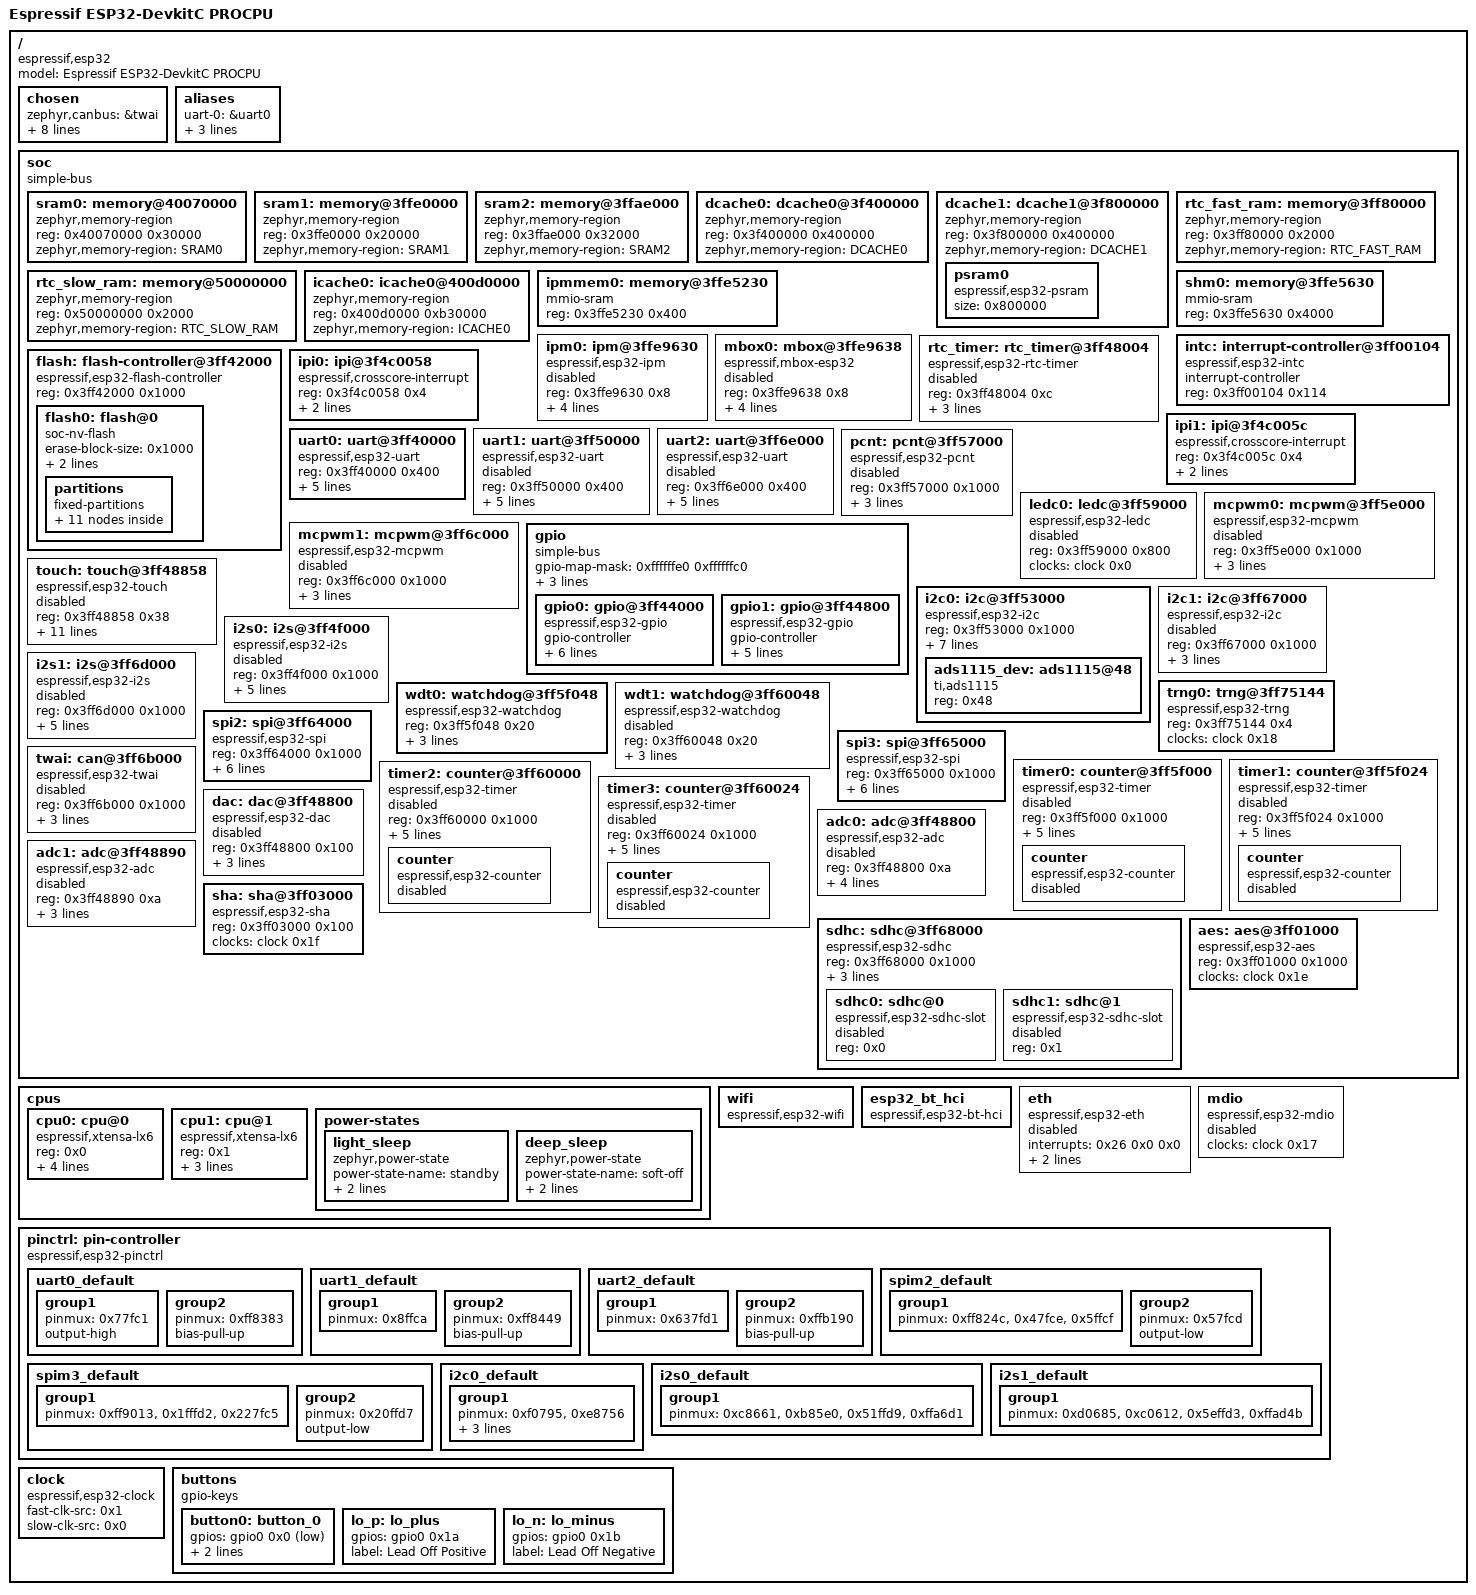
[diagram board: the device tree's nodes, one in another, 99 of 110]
/dts-v1/;

/* node '/' defined in zephyr/dts/common/skeleton.dtsi:9 */
/ {
	#address-cells = < 0x1 >;                 /* in zephyr/dts/common/skeleton.dtsi:10 */
	#size-cells = < 0x1 >;                    /* in zephyr/dts/common/skeleton.dtsi:11 */
	model = "Espressif ESP32-DevkitC PROCPU"; /* in zephyr/boards/espressif/esp32_devkitc/esp32_devkitc_procpu.dts:15 */
	compatible = "espressif,esp32";           /* in zephyr/boards/espressif/esp32_devkitc/esp32_devkitc_procpu.dts:16 */

	/* node '/chosen' defined in zephyr/dts/common/skeleton.dtsi:13 */
	chosen {
		zephyr,canbus = &twai;                    /* in zephyr/dts/xtensa/espressif/esp32/esp32_common.dtsi:20 */
		zephyr,entropy = &trng0;                  /* in zephyr/dts/xtensa/espressif/esp32/esp32_common.dtsi:21 */
		zephyr,flash-controller = &flash;         /* in zephyr/dts/xtensa/espressif/esp32/esp32_common.dtsi:22 */
		zephyr,sram = &sram1;                     /* in zephyr/boards/espressif/esp32_devkitc/esp32_devkitc_procpu.dts:36 */
		zephyr,console = &uart0;                  /* in zephyr/boards/espressif/esp32_devkitc/esp32_devkitc_procpu.dts:37 */
		zephyr,shell-uart = &uart0;               /* in zephyr/boards/espressif/esp32_devkitc/esp32_devkitc_procpu.dts:38 */
		zephyr,flash = &flash0;                   /* in zephyr/boards/espressif/esp32_devkitc/esp32_devkitc_procpu.dts:39 */
		zephyr,code-partition = &slot0_partition; /* in zephyr/boards/espressif/esp32_devkitc/esp32_devkitc_procpu.dts:40 */
		zephyr,bt-hci = &esp32_bt_hci;            /* in zephyr/boards/espressif/esp32_devkitc/esp32_devkitc_procpu.dts:41 */
	};

	/* node '/aliases' defined in zephyr/dts/common/skeleton.dtsi:15 */
	aliases {
		uart-0 = &uart0;   /* in zephyr/boards/espressif/esp32_devkitc/esp32_devkitc_procpu.dts:19 */
		i2c-0 = &i2c0;     /* in zephyr/boards/espressif/esp32_devkitc/esp32_devkitc_procpu.dts:20 */
		sw0 = &button0;    /* in zephyr/boards/espressif/esp32_devkitc/esp32_devkitc_procpu.dts:21 */
		watchdog0 = &wdt0; /* in zephyr/boards/espressif/esp32_devkitc/esp32_devkitc_procpu.dts:22 */
	};

	/* node '/soc' defined in zephyr/dts/xtensa/xtensa.dtsi:10 */
	soc {
		#address-cells = < 0x1 >;  /* in zephyr/dts/xtensa/xtensa.dtsi:11 */
		#size-cells = < 0x1 >;     /* in zephyr/dts/xtensa/xtensa.dtsi:12 */
		compatible = "simple-bus"; /* in zephyr/dts/xtensa/xtensa.dtsi:13 */
		ranges;                    /* in zephyr/dts/xtensa/xtensa.dtsi:14 */

		/* node '/soc/memory@40070000' defined in zephyr/dts/xtensa/espressif/esp32/esp32_common.dtsi:106 */
		sram0: memory@40070000 {
			compatible = "zephyr,memory-region",
			             "mmio-sram";            /* in zephyr/dts/xtensa/espressif/esp32/esp32_common.dtsi:107 */
			reg = < 0x40070000 0x30000 >;        /* in zephyr/dts/xtensa/espressif/esp32/esp32_common.dtsi:108 */
			zephyr,memory-region = "SRAM0";      /* in zephyr/dts/xtensa/espressif/esp32/esp32_common.dtsi:109 */
		};

		/* node '/soc/memory@3ffe0000' defined in zephyr/dts/xtensa/espressif/esp32/esp32_common.dtsi:112 */
		sram1: memory@3ffe0000 {
			compatible = "zephyr,memory-region",
			             "mmio-sram";            /* in zephyr/dts/xtensa/espressif/esp32/esp32_common.dtsi:113 */
			reg = < 0x3ffe0000 0x20000 >;        /* in zephyr/dts/xtensa/espressif/esp32/esp32_common.dtsi:114 */
			zephyr,memory-region = "SRAM1";      /* in zephyr/dts/xtensa/espressif/esp32/esp32_common.dtsi:115 */
		};

		/* node '/soc/memory@3ffae000' defined in zephyr/dts/xtensa/espressif/esp32/esp32_common.dtsi:118 */
		sram2: memory@3ffae000 {
			compatible = "zephyr,memory-region",
			             "mmio-sram";            /* in zephyr/dts/xtensa/espressif/esp32/esp32_common.dtsi:119 */
			reg = < 0x3ffae000 0x32000 >;        /* in zephyr/dts/xtensa/espressif/esp32/esp32_common.dtsi:120 */
			zephyr,memory-region = "SRAM2";      /* in zephyr/dts/xtensa/espressif/esp32/esp32_common.dtsi:121 */
		};

		/* node '/soc/dcache0@3f400000' defined in zephyr/dts/xtensa/espressif/esp32/esp32_common.dtsi:124 */
		dcache0: dcache0@3f400000 {
			compatible = "zephyr,memory-region",
			             "mmio-sram";            /* in zephyr/dts/xtensa/espressif/esp32/esp32_common.dtsi:125 */
			reg = < 0x3f400000 0x400000 >;       /* in zephyr/dts/xtensa/espressif/esp32/esp32_common.dtsi:126 */
			zephyr,memory-region = "DCACHE0";    /* in zephyr/dts/xtensa/espressif/esp32/esp32_common.dtsi:127 */
		};

		/* node '/soc/dcache1@3f800000' defined in zephyr/dts/xtensa/espressif/esp32/esp32_common.dtsi:130 */
		dcache1: dcache1@3f800000 {
			compatible = "zephyr,memory-region",
			             "mmio-sram";            /* in zephyr/dts/xtensa/espressif/esp32/esp32_common.dtsi:131 */
			reg = < 0x3f800000 0x400000 >;       /* in zephyr/dts/xtensa/espressif/esp32/esp32_common.dtsi:132 */
			zephyr,memory-region = "DCACHE1";    /* in zephyr/dts/xtensa/espressif/esp32/esp32_common.dtsi:133 */

			/* node '/soc/dcache1@3f800000/psram0' defined in zephyr/dts/xtensa/espressif/esp32/esp32_common.dtsi:135 */
			psram0: psram0 {
				compatible = "espressif,esp32-psram"; /* in zephyr/dts/xtensa/espressif/esp32/esp32_common.dtsi:136 */
				size = < 0x800000 >;                  /* in zephyr/dts/xtensa/espressif/esp32/esp32_wrover_e_n4r8.dtsi:26 */
			};
		};

		/* node '/soc/memory@3ff80000' defined in zephyr/dts/xtensa/espressif/esp32/esp32_common.dtsi:141 */
		rtc_fast_ram: memory@3ff80000 {
			compatible = "zephyr,memory-region",
			             "mmio-sram";              /* in zephyr/dts/xtensa/espressif/esp32/esp32_common.dtsi:142 */
			reg = < 0x3ff80000 0x2000 >;           /* in zephyr/dts/xtensa/espressif/esp32/esp32_common.dtsi:143 */
			zephyr,memory-region = "RTC_FAST_RAM"; /* in zephyr/dts/xtensa/espressif/esp32/esp32_common.dtsi:144 */
		};

		/* node '/soc/memory@50000000' defined in zephyr/dts/xtensa/espressif/esp32/esp32_common.dtsi:147 */
		rtc_slow_ram: memory@50000000 {
			compatible = "zephyr,memory-region",
			             "mmio-sram";              /* in zephyr/dts/xtensa/espressif/esp32/esp32_common.dtsi:148 */
			reg = < 0x50000000 0x2000 >;           /* in zephyr/dts/xtensa/espressif/esp32/esp32_common.dtsi:149 */
			zephyr,memory-region = "RTC_SLOW_RAM"; /* in zephyr/dts/xtensa/espressif/esp32/esp32_common.dtsi:150 */
		};

		/* node '/soc/icache0@400d0000' defined in zephyr/dts/xtensa/espressif/esp32/esp32_common.dtsi:153 */
		icache0: icache0@400d0000 {
			compatible = "zephyr,memory-region",
			             "mmio-sram";            /* in zephyr/dts/xtensa/espressif/esp32/esp32_common.dtsi:154 */
			reg = < 0x400d0000 0xb30000 >;       /* in zephyr/dts/xtensa/espressif/esp32/esp32_common.dtsi:155 */
			zephyr,memory-region = "ICACHE0";    /* in zephyr/dts/xtensa/espressif/esp32/esp32_common.dtsi:156 */
		};

		/* node '/soc/memory@3ffe5230' defined in zephyr/dts/xtensa/espressif/esp32/esp32_common.dtsi:159 */
		ipmmem0: memory@3ffe5230 {
			compatible = "mmio-sram";   /* in zephyr/dts/xtensa/espressif/esp32/esp32_common.dtsi:160 */
			reg = < 0x3ffe5230 0x400 >; /* in zephyr/dts/xtensa/espressif/esp32/esp32_common.dtsi:161 */
			phandle = < 0x1 >;          /* in zephyr/dts/xtensa/espressif/esp32/esp32_common.dtsi:173 */
		};

		/* node '/soc/memory@3ffe5630' defined in zephyr/dts/xtensa/espressif/esp32/esp32_common.dtsi:164 */
		shm0: memory@3ffe5630 {
			compatible = "mmio-sram";    /* in zephyr/dts/xtensa/espressif/esp32/esp32_common.dtsi:165 */
			reg = < 0x3ffe5630 0x4000 >; /* in zephyr/dts/xtensa/espressif/esp32/esp32_common.dtsi:166 */
		};

		/* node '/soc/ipm@3ffe9630' defined in zephyr/dts/xtensa/espressif/esp32/esp32_common.dtsi:169 */
		ipm0: ipm@3ffe9630 {
			compatible = "espressif,esp32-ipm"; /* in zephyr/dts/xtensa/espressif/esp32/esp32_common.dtsi:170 */
			reg = < 0x3ffe9630 0x8 >;           /* in zephyr/dts/xtensa/espressif/esp32/esp32_common.dtsi:171 */
			status = "disabled";                /* in zephyr/dts/xtensa/espressif/esp32/esp32_common.dtsi:172 */
			shared-memory = < &ipmmem0 >;       /* in zephyr/dts/xtensa/espressif/esp32/esp32_common.dtsi:173 */
			shared-memory-size = < 0x400 >;     /* in zephyr/dts/xtensa/espressif/esp32/esp32_common.dtsi:174 */
			interrupts = < 0x18 0x0 0x0 >,
			             < 0x19 0x0 0x0 >;      /* in zephyr/dts/xtensa/espressif/esp32/esp32_common.dtsi:175 */
			interrupt-parent = < &intc >;       /* in zephyr/dts/xtensa/espressif/esp32/esp32_common.dtsi:177 */
		};

		/* node '/soc/mbox@3ffe9638' defined in zephyr/dts/xtensa/espressif/esp32/esp32_common.dtsi:180 */
		mbox0: mbox@3ffe9638 {
			compatible = "espressif,mbox-esp32"; /* in zephyr/dts/xtensa/espressif/esp32/esp32_common.dtsi:181 */
			reg = < 0x3ffe9638 0x8 >;            /* in zephyr/dts/xtensa/espressif/esp32/esp32_common.dtsi:182 */
			status = "disabled";                 /* in zephyr/dts/xtensa/espressif/esp32/esp32_common.dtsi:183 */
			shared-memory = < &ipmmem0 >;        /* in zephyr/dts/xtensa/espressif/esp32/esp32_common.dtsi:184 */
			shared-memory-size = < 0x400 >;      /* in zephyr/dts/xtensa/espressif/esp32/esp32_common.dtsi:185 */
			interrupts = < 0x18 0x0 0x0 >,
			             < 0x19 0x0 0x0 >;       /* in zephyr/dts/xtensa/espressif/esp32/esp32_common.dtsi:186 */
			interrupt-parent = < &intc >;        /* in zephyr/dts/xtensa/espressif/esp32/esp32_common.dtsi:188 */
			#mbox-cells = < 0x1 >;               /* in zephyr/dts/xtensa/espressif/esp32/esp32_common.dtsi:189 */
		};

		/* node '/soc/interrupt-controller@3ff00104' defined in zephyr/dts/xtensa/espressif/esp32/esp32_common.dtsi:192 */
		intc: interrupt-controller@3ff00104 {
			#interrupt-cells = < 0x3 >;          /* in zephyr/dts/xtensa/espressif/esp32/esp32_common.dtsi:193 */
			#address-cells = < 0x0 >;            /* in zephyr/dts/xtensa/espressif/esp32/esp32_common.dtsi:194 */
			compatible = "espressif,esp32-intc"; /* in zephyr/dts/xtensa/espressif/esp32/esp32_common.dtsi:195 */
			interrupt-controller;                /* in zephyr/dts/xtensa/espressif/esp32/esp32_common.dtsi:196 */
			reg = < 0x3ff00104 0x114 >;          /* in zephyr/dts/xtensa/espressif/esp32/esp32_common.dtsi:197 */
			status = "okay";                     /* in zephyr/dts/xtensa/espressif/esp32/esp32_common.dtsi:198 */
			phandle = < 0x2 >;                   /* in zephyr/dts/xtensa/espressif/esp32/esp32_common.dtsi:177 */
		};

		/* node '/soc/rtc_timer@3ff48004' defined in zephyr/dts/xtensa/espressif/esp32/esp32_common.dtsi:201 */
		rtc_timer: rtc_timer@3ff48004 {
			reg = < 0x3ff48004 0xc >;                 /* in zephyr/dts/xtensa/espressif/esp32/esp32_common.dtsi:202 */
			compatible = "espressif,esp32-rtc-timer"; /* in zephyr/dts/xtensa/espressif/esp32/esp32_common.dtsi:203 */
			clocks = < &clock 0x22 >;                 /* in zephyr/dts/xtensa/espressif/esp32/esp32_common.dtsi:204 */
			interrupts = < 0x2e 0x0 0x0 >;            /* in zephyr/dts/xtensa/espressif/esp32/esp32_common.dtsi:205 */
			interrupt-parent = < &intc >;             /* in zephyr/dts/xtensa/espressif/esp32/esp32_common.dtsi:206 */
			status = "disabled";                      /* in zephyr/dts/xtensa/espressif/esp32/esp32_common.dtsi:207 */
		};

		/* node '/soc/flash-controller@3ff42000' defined in zephyr/dts/xtensa/espressif/esp32/esp32_common.dtsi:210 */
		flash: flash-controller@3ff42000 {
			compatible = "espressif,esp32-flash-controller"; /* in zephyr/dts/xtensa/espressif/esp32/esp32_common.dtsi:211 */
			reg = < 0x3ff42000 0x1000 >;                     /* in zephyr/dts/xtensa/espressif/esp32/esp32_common.dtsi:212 */
			#address-cells = < 0x1 >;                        /* in zephyr/dts/xtensa/espressif/esp32/esp32_common.dtsi:213 */
			#size-cells = < 0x1 >;                           /* in zephyr/dts/xtensa/espressif/esp32/esp32_common.dtsi:214 */

			/* node '/soc/flash-controller@3ff42000/flash@0' defined in zephyr/dts/xtensa/espressif/esp32/esp32_common.dtsi:216 */
			flash0: flash@0 {
				compatible = "soc-nv-flash";   /* in zephyr/dts/xtensa/espressif/esp32/esp32_common.dtsi:217 */
				erase-block-size = < 0x1000 >; /* in zephyr/dts/xtensa/espressif/esp32/esp32_common.dtsi:218 */
				write-block-size = < 0x4 >;    /* in zephyr/dts/xtensa/espressif/esp32/esp32_common.dtsi:219 */
				reg = < 0x0 0x400000 >;        /* in zephyr/dts/xtensa/espressif/esp32/esp32_wrover_e_n4r8.dtsi:21 */

				/* node '/soc/flash-controller@3ff42000/flash@0/partitions' defined in zephyr/dts/vendor/espressif/partitions_0x1000_amp_4M.dtsi:8 */
				partitions {
					compatible = "fixed-partitions"; /* in zephyr/dts/vendor/espressif/partitions_0x1000_amp_4M.dtsi:9 */
					#address-cells = < 0x1 >;        /* in zephyr/dts/vendor/espressif/partitions_0x1000_amp_4M.dtsi:10 */
					#size-cells = < 0x1 >;           /* in zephyr/dts/vendor/espressif/partitions_0x1000_amp_4M.dtsi:11 */

					/* node '/soc/flash-controller@3ff42000/flash@0/partitions/partition@1000' defined in zephyr/dts/vendor/espressif/partitions_0x1000_amp_4M.dtsi:13 */
					boot_partition: partition@1000 {
						label = "mcuboot";       /* in zephyr/dts/vendor/espressif/partitions_0x1000_amp_4M.dtsi:14 */
						reg = < 0x1000 0xf000 >; /* in zephyr/dts/vendor/espressif/partitions_0x1000_amp_4M.dtsi:15 */
					};

					/* node '/soc/flash-controller@3ff42000/flash@0/partitions/partition@10000' defined in zephyr/dts/vendor/espressif/partitions_0x1000_amp_4M.dtsi:18 */
					sys_partition: partition@10000 {
						label = "sys";             /* in zephyr/dts/vendor/espressif/partitions_0x1000_amp_4M.dtsi:19 */
						reg = < 0x10000 0x10000 >; /* in zephyr/dts/vendor/espressif/partitions_0x1000_amp_4M.dtsi:20 */
					};

					/* node '/soc/flash-controller@3ff42000/flash@0/partitions/partition@20000' defined in zephyr/dts/vendor/espressif/partitions_0x1000_amp_4M.dtsi:23 */
					slot0_partition: partition@20000 {
						label = "image-0";          /* in zephyr/dts/vendor/espressif/partitions_0x1000_amp_4M.dtsi:24 */
						reg = < 0x20000 0x150000 >; /* in zephyr/dts/vendor/espressif/partitions_0x1000_amp_4M.dtsi:25 */
					};

					/* node '/soc/flash-controller@3ff42000/flash@0/partitions/partition@170000' defined in zephyr/dts/vendor/espressif/partitions_0x1000_amp_4M.dtsi:28 */
					slot1_partition: partition@170000 {
						label = "image-1";           /* in zephyr/dts/vendor/espressif/partitions_0x1000_amp_4M.dtsi:29 */
						reg = < 0x170000 0x150000 >; /* in zephyr/dts/vendor/espressif/partitions_0x1000_amp_4M.dtsi:30 */
					};

					/* node '/soc/flash-controller@3ff42000/flash@0/partitions/partition@2c0000' defined in zephyr/dts/vendor/espressif/partitions_0x1000_amp_4M.dtsi:33 */
					slot0_appcpu_partition: partition@2c0000 {
						label = "image-0-appcpu";   /* in zephyr/dts/vendor/espressif/partitions_0x1000_amp_4M.dtsi:34 */
						reg = < 0x2c0000 0x70000 >; /* in zephyr/dts/vendor/espressif/partitions_0x1000_amp_4M.dtsi:35 */
					};

					/* node '/soc/flash-controller@3ff42000/flash@0/partitions/partition@330000' defined in zephyr/dts/vendor/espressif/partitions_0x1000_amp_4M.dtsi:38 */
					slot1_appcpu_partition: partition@330000 {
						label = "image-1-appcpu";   /* in zephyr/dts/vendor/espressif/partitions_0x1000_amp_4M.dtsi:39 */
						reg = < 0x330000 0x70000 >; /* in zephyr/dts/vendor/espressif/partitions_0x1000_amp_4M.dtsi:40 */
					};

					/* node '/soc/flash-controller@3ff42000/flash@0/partitions/partition@3a0000' defined in zephyr/dts/vendor/espressif/partitions_0x1000_amp_4M.dtsi:43 */
					slot0_lpcore_partition: partition@3a0000 {
						label = "image-0-lpcore";  /* in zephyr/dts/vendor/espressif/partitions_0x1000_amp_4M.dtsi:44 */
						reg = < 0x3a0000 0x8000 >; /* in zephyr/dts/vendor/espressif/partitions_0x1000_amp_4M.dtsi:45 */
					};

					/* node '/soc/flash-controller@3ff42000/flash@0/partitions/partition@3a8000' defined in zephyr/dts/vendor/espressif/partitions_0x1000_amp_4M.dtsi:48 */
					slot1_lpcore_partition: partition@3a8000 {
						label = "image-1-lpcore";  /* in zephyr/dts/vendor/espressif/partitions_0x1000_amp_4M.dtsi:49 */
						reg = < 0x3a8000 0x8000 >; /* in zephyr/dts/vendor/espressif/partitions_0x1000_amp_4M.dtsi:50 */
					};

					/* node '/soc/flash-controller@3ff42000/flash@0/partitions/partition@3b0000' defined in zephyr/dts/vendor/espressif/partitions_0x1000_amp_4M.dtsi:53 */
					storage_partition: partition@3b0000 {
						label = "storage";          /* in zephyr/dts/vendor/espressif/partitions_0x1000_amp_4M.dtsi:54 */
						reg = < 0x3b0000 0x30000 >; /* in zephyr/dts/vendor/espressif/partitions_0x1000_amp_4M.dtsi:55 */
					};

					/* node '/soc/flash-controller@3ff42000/flash@0/partitions/partition@3e0000' defined in zephyr/dts/vendor/espressif/partitions_0x1000_amp_4M.dtsi:58 */
					scratch_partition: partition@3e0000 {
						label = "image-scratch";    /* in zephyr/dts/vendor/espressif/partitions_0x1000_amp_4M.dtsi:59 */
						reg = < 0x3e0000 0x1f000 >; /* in zephyr/dts/vendor/espressif/partitions_0x1000_amp_4M.dtsi:60 */
					};

					/* node '/soc/flash-controller@3ff42000/flash@0/partitions/partition@3ff000' defined in zephyr/dts/vendor/espressif/partitions_0x1000_amp_4M.dtsi:63 */
					coredump_partition: partition@3ff000 {
						label = "coredump";        /* in zephyr/dts/vendor/espressif/partitions_0x1000_amp_4M.dtsi:64 */
						reg = < 0x3ff000 0x1000 >; /* in zephyr/dts/vendor/espressif/partitions_0x1000_amp_4M.dtsi:65 */
					};
				};
			};
		};

		/* node '/soc/ipi@3f4c0058' defined in zephyr/dts/xtensa/espressif/esp32/esp32_common.dtsi:224 */
		ipi0: ipi@3f4c0058 {
			compatible = "espressif,crosscore-interrupt"; /* in zephyr/dts/xtensa/espressif/esp32/esp32_common.dtsi:225 */
			reg = < 0x3f4c0058 0x4 >;                     /* in zephyr/dts/xtensa/espressif/esp32/esp32_common.dtsi:226 */
			interrupts = < 0x18 0x0 0x0 >;                /* in zephyr/dts/xtensa/espressif/esp32/esp32_common.dtsi:227 */
			interrupt-parent = < &intc >;                 /* in zephyr/dts/xtensa/espressif/esp32/esp32_common.dtsi:228 */
		};

		/* node '/soc/ipi@3f4c005c' defined in zephyr/dts/xtensa/espressif/esp32/esp32_common.dtsi:231 */
		ipi1: ipi@3f4c005c {
			compatible = "espressif,crosscore-interrupt"; /* in zephyr/dts/xtensa/espressif/esp32/esp32_common.dtsi:232 */
			reg = < 0x3f4c005c 0x4 >;                     /* in zephyr/dts/xtensa/espressif/esp32/esp32_common.dtsi:233 */
			interrupts = < 0x19 0x0 0x0 >;                /* in zephyr/dts/xtensa/espressif/esp32/esp32_common.dtsi:234 */
			interrupt-parent = < &intc >;                 /* in zephyr/dts/xtensa/espressif/esp32/esp32_common.dtsi:235 */
		};

		/* node '/soc/uart@3ff40000' defined in zephyr/dts/xtensa/espressif/esp32/esp32_common.dtsi:238 */
		uart0: uart@3ff40000 {
			compatible = "espressif,esp32-uart"; /* in zephyr/dts/xtensa/espressif/esp32/esp32_common.dtsi:239 */
			reg = < 0x3ff40000 0x400 >;          /* in zephyr/dts/xtensa/espressif/esp32/esp32_common.dtsi:240 */
			interrupts = < 0x22 0x0 0x0 >;       /* in zephyr/dts/xtensa/espressif/esp32/esp32_common.dtsi:241 */
			interrupt-parent = < &intc >;        /* in zephyr/dts/xtensa/espressif/esp32/esp32_common.dtsi:242 */
			clocks = < &clock 0x1 >;             /* in zephyr/dts/xtensa/espressif/esp32/esp32_common.dtsi:243 */
			status = "okay";                     /* in zephyr/boards/espressif/esp32_devkitc/esp32_devkitc_procpu.dts:46 */
			current-speed = < 0x1c200 >;         /* in zephyr/boards/espressif/esp32_devkitc/esp32_devkitc_procpu.dts:47 */
			pinctrl-0 = < &uart0_default >;      /* in zephyr/boards/espressif/esp32_devkitc/esp32_devkitc_procpu.dts:48 */
			pinctrl-names = "default";           /* in zephyr/boards/espressif/esp32_devkitc/esp32_devkitc_procpu.dts:49 */
		};

		/* node '/soc/uart@3ff50000' defined in zephyr/dts/xtensa/espressif/esp32/esp32_common.dtsi:247 */
		uart1: uart@3ff50000 {
			compatible = "espressif,esp32-uart"; /* in zephyr/dts/xtensa/espressif/esp32/esp32_common.dtsi:248 */
			reg = < 0x3ff50000 0x400 >;          /* in zephyr/dts/xtensa/espressif/esp32/esp32_common.dtsi:249 */
			interrupts = < 0x23 0x0 0x0 >;       /* in zephyr/dts/xtensa/espressif/esp32/esp32_common.dtsi:250 */
			interrupt-parent = < &intc >;        /* in zephyr/dts/xtensa/espressif/esp32/esp32_common.dtsi:251 */
			clocks = < &clock 0x2 >;             /* in zephyr/dts/xtensa/espressif/esp32/esp32_common.dtsi:252 */
			status = "disabled";                 /* in zephyr/dts/xtensa/espressif/esp32/esp32_common.dtsi:253 */
			current-speed = < 0x1c200 >;         /* in zephyr/boards/espressif/esp32_devkitc/esp32_devkitc_procpu.dts:53 */
			pinctrl-0 = < &uart1_default >;      /* in zephyr/boards/espressif/esp32_devkitc/esp32_devkitc_procpu.dts:54 */
			pinctrl-names = "default";           /* in zephyr/boards/espressif/esp32_devkitc/esp32_devkitc_procpu.dts:55 */
		};

		/* node '/soc/uart@3ff6e000' defined in zephyr/dts/xtensa/espressif/esp32/esp32_common.dtsi:256 */
		uart2: uart@3ff6e000 {
			compatible = "espressif,esp32-uart"; /* in zephyr/dts/xtensa/espressif/esp32/esp32_common.dtsi:257 */
			reg = < 0x3ff6e000 0x400 >;          /* in zephyr/dts/xtensa/espressif/esp32/esp32_common.dtsi:258 */
			interrupts = < 0x24 0x0 0x0 >;       /* in zephyr/dts/xtensa/espressif/esp32/esp32_common.dtsi:259 */
			interrupt-parent = < &intc >;        /* in zephyr/dts/xtensa/espressif/esp32/esp32_common.dtsi:260 */
			clocks = < &clock 0x3 >;             /* in zephyr/dts/xtensa/espressif/esp32/esp32_common.dtsi:261 */
			status = "disabled";                 /* in zephyr/dts/xtensa/espressif/esp32/esp32_common.dtsi:262 */
			current-speed = < 0x1c200 >;         /* in zephyr/boards/espressif/esp32_devkitc/esp32_devkitc_procpu.dts:59 */
			pinctrl-0 = < &uart2_default >;      /* in zephyr/boards/espressif/esp32_devkitc/esp32_devkitc_procpu.dts:60 */
			pinctrl-names = "default";           /* in zephyr/boards/espressif/esp32_devkitc/esp32_devkitc_procpu.dts:61 */
		};

		/* node '/soc/pcnt@3ff57000' defined in zephyr/dts/xtensa/espressif/esp32/esp32_common.dtsi:265 */
		pcnt: pcnt@3ff57000 {
			compatible = "espressif,esp32-pcnt"; /* in zephyr/dts/xtensa/espressif/esp32/esp32_common.dtsi:266 */
			reg = < 0x3ff57000 0x1000 >;         /* in zephyr/dts/xtensa/espressif/esp32/esp32_common.dtsi:267 */
			interrupts = < 0x30 0x0 0x0 >;       /* in zephyr/dts/xtensa/espressif/esp32/esp32_common.dtsi:268 */
			interrupt-parent = < &intc >;        /* in zephyr/dts/xtensa/espressif/esp32/esp32_common.dtsi:269 */
			clocks = < &clock 0xf >;             /* in zephyr/dts/xtensa/espressif/esp32/esp32_common.dtsi:270 */
			status = "disabled";                 /* in zephyr/dts/xtensa/espressif/esp32/esp32_common.dtsi:271 */
		};

		/* node '/soc/ledc@3ff59000' defined in zephyr/dts/xtensa/espressif/esp32/esp32_common.dtsi:274 */
		ledc0: ledc@3ff59000 {
			compatible = "espressif,esp32-ledc"; /* in zephyr/dts/xtensa/espressif/esp32/esp32_common.dtsi:275 */
			#pwm-cells = < 0x3 >;                /* in zephyr/dts/xtensa/espressif/esp32/esp32_common.dtsi:276 */
			reg = < 0x3ff59000 0x800 >;          /* in zephyr/dts/xtensa/espressif/esp32/esp32_common.dtsi:277 */
			clocks = < &clock 0x0 >;             /* in zephyr/dts/xtensa/espressif/esp32/esp32_common.dtsi:278 */
			status = "disabled";                 /* in zephyr/dts/xtensa/espressif/esp32/esp32_common.dtsi:279 */
		};

		/* node '/soc/mcpwm@3ff5e000' defined in zephyr/dts/xtensa/espressif/esp32/esp32_common.dtsi:282 */
		mcpwm0: mcpwm@3ff5e000 {
			compatible = "espressif,esp32-mcpwm"; /* in zephyr/dts/xtensa/espressif/esp32/esp32_common.dtsi:283 */
			reg = < 0x3ff5e000 0x1000 >;          /* in zephyr/dts/xtensa/espressif/esp32/esp32_common.dtsi:284 */
			interrupts = < 0x27 0x0 0x0 >;        /* in zephyr/dts/xtensa/espressif/esp32/esp32_common.dtsi:285 */
			interrupt-parent = < &intc >;         /* in zephyr/dts/xtensa/espressif/esp32/esp32_common.dtsi:286 */
			clocks = < &clock 0xa >;              /* in zephyr/dts/xtensa/espressif/esp32/esp32_common.dtsi:287 */
			#pwm-cells = < 0x3 >;                 /* in zephyr/dts/xtensa/espressif/esp32/esp32_common.dtsi:288 */
			status = "disabled";                  /* in zephyr/dts/xtensa/espressif/esp32/esp32_common.dtsi:289 */
		};

		/* node '/soc/mcpwm@3ff6c000' defined in zephyr/dts/xtensa/espressif/esp32/esp32_common.dtsi:292 */
		mcpwm1: mcpwm@3ff6c000 {
			compatible = "espressif,esp32-mcpwm"; /* in zephyr/dts/xtensa/espressif/esp32/esp32_common.dtsi:293 */
			reg = < 0x3ff6c000 0x1000 >;          /* in zephyr/dts/xtensa/espressif/esp32/esp32_common.dtsi:294 */
			interrupts = < 0x28 0x0 0x0 >;        /* in zephyr/dts/xtensa/espressif/esp32/esp32_common.dtsi:295 */
			interrupt-parent = < &intc >;         /* in zephyr/dts/xtensa/espressif/esp32/esp32_common.dtsi:296 */
			clocks = < &clock 0xb >;              /* in zephyr/dts/xtensa/espressif/esp32/esp32_common.dtsi:297 */
			#pwm-cells = < 0x3 >;                 /* in zephyr/dts/xtensa/espressif/esp32/esp32_common.dtsi:298 */
			status = "disabled";                  /* in zephyr/dts/xtensa/espressif/esp32/esp32_common.dtsi:299 */
		};

		/* node '/soc/gpio' defined in zephyr/dts/xtensa/espressif/esp32/esp32_common.dtsi:302 */
		gpio: gpio {
			compatible = "simple-bus";                                     /* in zephyr/dts/xtensa/espressif/esp32/esp32_common.dtsi:303 */
			gpio-map-mask = < 0xffffffe0 0xffffffc0 >;                     /* in zephyr/dts/xtensa/espressif/esp32/esp32_common.dtsi:304 */
			gpio-map-pass-thru = < 0x1f 0x3f >;                            /* in zephyr/dts/xtensa/espressif/esp32/esp32_common.dtsi:305 */
			gpio-map = < 0x0 0x0 &gpio0 0x0 0x0 0x20 0x0 &gpio1 0x0 0x0 >; /* in zephyr/dts/xtensa/espressif/esp32/esp32_common.dtsi:306 */
			#gpio-cells = < 0x2 >;                                         /* in zephyr/dts/xtensa/espressif/esp32/esp32_common.dtsi:308 */
			#address-cells = < 0x1 >;                                      /* in zephyr/dts/xtensa/espressif/esp32/esp32_common.dtsi:309 */
			#size-cells = < 0x1 >;                                         /* in zephyr/dts/xtensa/espressif/esp32/esp32_common.dtsi:310 */
			ranges;                                                        /* in zephyr/dts/xtensa/espressif/esp32/esp32_common.dtsi:311 */

			/* node '/soc/gpio/gpio@3ff44000' defined in zephyr/dts/xtensa/espressif/esp32/esp32_common.dtsi:313 */
			gpio0: gpio@3ff44000 {
				compatible = "espressif,esp32-gpio"; /* in zephyr/dts/xtensa/espressif/esp32/esp32_common.dtsi:314 */
				gpio-controller;                     /* in zephyr/dts/xtensa/espressif/esp32/esp32_common.dtsi:315 */
				#gpio-cells = < 0x2 >;               /* in zephyr/dts/xtensa/espressif/esp32/esp32_common.dtsi:316 */
				reg = < 0x3ff44000 0x800 >;          /* in zephyr/dts/xtensa/espressif/esp32/esp32_common.dtsi:317 */
				interrupts = < 0x16 0x0 0x0 >;       /* in zephyr/dts/xtensa/espressif/esp32/esp32_common.dtsi:318 */
				interrupt-parent = < &intc >;        /* in zephyr/dts/xtensa/espressif/esp32/esp32_common.dtsi:319 */
				ngpios = < 0x20 >;                   /* in zephyr/dts/xtensa/espressif/esp32/esp32_common.dtsi:325 */
				gpio-reserved-ranges = < 0x6 0x6 >,
				                       < 0x10 0x2 >,
				                       < 0x14 0x1 >,
				                       < 0x18 0x1 >,
				                       < 0x1c 0x4 >; /* in zephyr/dts/xtensa/espressif/esp32/esp32_wrover_e_n4r8.dtsi:11 */
				status = "okay";                     /* in zephyr/boards/espressif/esp32_devkitc/esp32_devkitc_procpu.dts:65 */
				phandle = < 0x7 >;                   /* in zephyr/dts/xtensa/espressif/esp32/esp32_common.dtsi:306 */
			};

			/* node '/soc/gpio/gpio@3ff44800' defined in zephyr/dts/xtensa/espressif/esp32/esp32_common.dtsi:328 */
			gpio1: gpio@3ff44800 {
				compatible = "espressif,esp32-gpio"; /* in zephyr/dts/xtensa/espressif/esp32/esp32_common.dtsi:329 */
				gpio-controller;                     /* in zephyr/dts/xtensa/espressif/esp32/esp32_common.dtsi:330 */
				#gpio-cells = < 0x2 >;               /* in zephyr/dts/xtensa/espressif/esp32/esp32_common.dtsi:331 */
				reg = < 0x3ff44800 0x800 >;          /* in zephyr/dts/xtensa/espressif/esp32/esp32_common.dtsi:332 */
				interrupts = < 0x16 0x0 0x0 >;       /* in zephyr/dts/xtensa/espressif/esp32/esp32_common.dtsi:333 */
				interrupt-parent = < &intc >;        /* in zephyr/dts/xtensa/espressif/esp32/esp32_common.dtsi:334 */
				ngpios = < 0x8 >;                    /* in zephyr/dts/xtensa/espressif/esp32/esp32_common.dtsi:335 */
				gpio-reserved-ranges = < 0x5 0x2 >;  /* in zephyr/dts/xtensa/espressif/esp32/esp32_wrover_e_n4r8.dtsi:16 */
				status = "okay";                     /* in zephyr/boards/espressif/esp32_devkitc/esp32_devkitc_procpu.dts:69 */
				phandle = < 0x8 >;                   /* in zephyr/dts/xtensa/espressif/esp32/esp32_common.dtsi:306 */
			};
		};

		/* node '/soc/touch@3ff48858' defined in zephyr/dts/xtensa/espressif/esp32/esp32_common.dtsi:339 */
		touch: touch@3ff48858 {
			compatible = "espressif,esp32-touch"; /* in zephyr/dts/xtensa/espressif/esp32/esp32_common.dtsi:340 */
			reg = < 0x3ff48858 0x38 >;            /* in zephyr/dts/xtensa/espressif/esp32/esp32_common.dtsi:341 */
			interrupts = < 0x2e 0x0 0x0 >;        /* in zephyr/dts/xtensa/espressif/esp32/esp32_common.dtsi:342 */
			interrupt-parent = < &intc >;         /* in zephyr/dts/xtensa/espressif/esp32/esp32_common.dtsi:343 */
			status = "disabled";                  /* in zephyr/dts/xtensa/espressif/esp32/esp32_common.dtsi:344 */
			debounce-interval-ms = < 0x1e >;      /* in zephyr/boards/espressif/esp32_devkitc/esp32_devkitc_procpu.dts:73 */
			href-microvolt = < 0x2932e0 >;        /* in zephyr/boards/espressif/esp32_devkitc/esp32_devkitc_procpu.dts:74 */
			lref-microvolt = < 0x7a120 >;         /* in zephyr/boards/espressif/esp32_devkitc/esp32_devkitc_procpu.dts:75 */
			href-atten-microvolt = < 0xf4240 >;   /* in zephyr/boards/espressif/esp32_devkitc/esp32_devkitc_procpu.dts:76 */
			filter-mode = < 0x2 >;                /* in zephyr/boards/espressif/esp32_devkitc/esp32_devkitc_procpu.dts:77 */
			filter-debounce-cnt = < 0x1 >;        /* in zephyr/boards/espressif/esp32_devkitc/esp32_devkitc_procpu.dts:78 */
			filter-noise-thr = < 0x0 >;           /* in zephyr/boards/espressif/esp32_devkitc/esp32_devkitc_procpu.dts:79 */
			filter-jitter-step = < 0x4 >;         /* in zephyr/boards/espressif/esp32_devkitc/esp32_devkitc_procpu.dts:80 */
			filter-smooth-level = < 0x1 >;        /* in zephyr/boards/espressif/esp32_devkitc/esp32_devkitc_procpu.dts:81 */
		};

		/* node '/soc/i2c@3ff53000' defined in zephyr/dts/xtensa/espressif/esp32/esp32_common.dtsi:347 */
		i2c0: i2c@3ff53000 {
			compatible = "espressif,esp32-i2c"; /* in zephyr/dts/xtensa/espressif/esp32/esp32_common.dtsi:348 */
			#address-cells = < 0x1 >;           /* in zephyr/dts/xtensa/espressif/esp32/esp32_common.dtsi:349 */
			#size-cells = < 0x0 >;              /* in zephyr/dts/xtensa/espressif/esp32/esp32_common.dtsi:350 */
			reg = < 0x3ff53000 0x1000 >;        /* in zephyr/dts/xtensa/espressif/esp32/esp32_common.dtsi:351 */
			interrupts = < 0x31 0x0 0x0 >;      /* in zephyr/dts/xtensa/espressif/esp32/esp32_common.dtsi:352 */
			interrupt-parent = < &intc >;       /* in zephyr/dts/xtensa/espressif/esp32/esp32_common.dtsi:353 */
			clocks = < &clock 0x4 >;            /* in zephyr/dts/xtensa/espressif/esp32/esp32_common.dtsi:354 */
			status = "okay";                    /* in zephyr/boards/espressif/esp32_devkitc/esp32_devkitc_procpu.dts:85 */
			sda-gpios = < &gpio0 0x15 0x6 >;    /* in zephyr/boards/espressif/esp32_devkitc/esp32_devkitc_procpu.dts:87 */
			scl-gpios = < &gpio0 0x16 0x6 >;    /* in zephyr/boards/espressif/esp32_devkitc/esp32_devkitc_procpu.dts:88 */
			pinctrl-0 = < &i2c0_default >;      /* in zephyr/boards/espressif/esp32_devkitc/esp32_devkitc_procpu.dts:89 */
			pinctrl-names = "default";          /* in zephyr/boards/espressif/esp32_devkitc/esp32_devkitc_procpu.dts:90 */
			clock-frequency = < 0x186a0 >;      /* in zephyr/trabalho/app.overlay:16 */

			/* node '/soc/i2c@3ff53000/ads1115@48' defined in zephyr/trabalho/app.overlay:18 */
			ads1115_dev: ads1115@48 {
				compatible = "ti,ads1115";   /* in zephyr/trabalho/app.overlay:19 */
				reg = < 0x48 >;              /* in zephyr/trabalho/app.overlay:20 */
				#io-channel-cells = < 0x1 >; /* in zephyr/trabalho/app.overlay:21 */
			};
		};

		/* node '/soc/i2c@3ff67000' defined in zephyr/dts/xtensa/espressif/esp32/esp32_common.dtsi:358 */
		i2c1: i2c@3ff67000 {
			compatible = "espressif,esp32-i2c"; /* in zephyr/dts/xtensa/espressif/esp32/esp32_common.dtsi:359 */
			#address-cells = < 0x1 >;           /* in zephyr/dts/xtensa/espressif/esp32/esp32_common.dtsi:360 */
			#size-cells = < 0x0 >;              /* in zephyr/dts/xtensa/espressif/esp32/esp32_common.dtsi:361 */
			reg = < 0x3ff67000 0x1000 >;        /* in zephyr/dts/xtensa/espressif/esp32/esp32_common.dtsi:362 */
			interrupts = < 0x32 0x0 0x0 >;      /* in zephyr/dts/xtensa/espressif/esp32/esp32_common.dtsi:363 */
			interrupt-parent = < &intc >;       /* in zephyr/dts/xtensa/espressif/esp32/esp32_common.dtsi:364 */
			clocks = < &clock 0x5 >;            /* in zephyr/dts/xtensa/espressif/esp32/esp32_common.dtsi:365 */
			status = "disabled";                /* in zephyr/dts/xtensa/espressif/esp32/esp32_common.dtsi:366 */
		};

		/* node '/soc/i2s@3ff4f000' defined in zephyr/dts/xtensa/espressif/esp32/esp32_common.dtsi:369 */
		i2s0: i2s@3ff4f000 {
			compatible = "espressif,esp32-i2s"; /* in zephyr/dts/xtensa/espressif/esp32/esp32_common.dtsi:370 */
			#address-cells = < 0x1 >;           /* in zephyr/dts/xtensa/espressif/esp32/esp32_common.dtsi:371 */
			#size-cells = < 0x0 >;              /* in zephyr/dts/xtensa/espressif/esp32/esp32_common.dtsi:372 */
			reg = < 0x3ff4f000 0x1000 >;        /* in zephyr/dts/xtensa/espressif/esp32/esp32_common.dtsi:373 */
			interrupts = < 0x20 0x0 0x0 >,
			             < 0x20 0x0 0x0 >;      /* in zephyr/dts/xtensa/espressif/esp32/esp32_common.dtsi:374 */
			interrupt-names = "rx",
			                  "tx";             /* in zephyr/dts/xtensa/espressif/esp32/esp32_common.dtsi:376 */
			interrupt-parent = < &intc >;       /* in zephyr/dts/xtensa/espressif/esp32/esp32_common.dtsi:377 */
			clocks = < &clock 0x6 >;            /* in zephyr/dts/xtensa/espressif/esp32/esp32_common.dtsi:378 */
			unit = < 0x0 >;                     /* in zephyr/dts/xtensa/espressif/esp32/esp32_common.dtsi:379 */
			status = "disabled";                /* in zephyr/dts/xtensa/espressif/esp32/esp32_common.dtsi:380 */
			pinctrl-0 = < &i2s0_default >;      /* in zephyr/boards/espressif/esp32_devkitc/esp32_devkitc_procpu.dts:94 */
			pinctrl-names = "default";          /* in zephyr/boards/espressif/esp32_devkitc/esp32_devkitc_procpu.dts:95 */
		};

		/* node '/soc/i2s@3ff6d000' defined in zephyr/dts/xtensa/espressif/esp32/esp32_common.dtsi:383 */
		i2s1: i2s@3ff6d000 {
			compatible = "espressif,esp32-i2s"; /* in zephyr/dts/xtensa/espressif/esp32/esp32_common.dtsi:384 */
			#address-cells = < 0x1 >;           /* in zephyr/dts/xtensa/espressif/esp32/esp32_common.dtsi:385 */
			#size-cells = < 0x0 >;              /* in zephyr/dts/xtensa/espressif/esp32/esp32_common.dtsi:386 */
			reg = < 0x3ff6d000 0x1000 >;        /* in zephyr/dts/xtensa/espressif/esp32/esp32_common.dtsi:387 */
			interrupts = < 0x21 0x0 0x0 >,
			             < 0x21 0x0 0x0 >;      /* in zephyr/dts/xtensa/espressif/esp32/esp32_common.dtsi:388 */
			interrupt-names = "rx",
			                  "tx";             /* in zephyr/dts/xtensa/espressif/esp32/esp32_common.dtsi:390 */
			interrupt-parent = < &intc >;       /* in zephyr/dts/xtensa/espressif/esp32/esp32_common.dtsi:391 */
			clocks = < &clock 0x7 >;            /* in zephyr/dts/xtensa/espressif/esp32/esp32_common.dtsi:392 */
			unit = < 0x1 >;                     /* in zephyr/dts/xtensa/espressif/esp32/esp32_common.dtsi:393 */
			status = "disabled";                /* in zephyr/dts/xtensa/espressif/esp32/esp32_common.dtsi:394 */
			pinctrl-0 = < &i2s1_default >;      /* in zephyr/boards/espressif/esp32_devkitc/esp32_devkitc_procpu.dts:99 */
			pinctrl-names = "default";          /* in zephyr/boards/espressif/esp32_devkitc/esp32_devkitc_procpu.dts:100 */
		};

		/* node '/soc/trng@3ff75144' defined in zephyr/dts/xtensa/espressif/esp32/esp32_common.dtsi:397 */
		trng0: trng@3ff75144 {
			compatible = "espressif,esp32-trng"; /* in zephyr/dts/xtensa/espressif/esp32/esp32_common.dtsi:398 */
			reg = < 0x3ff75144 0x4 >;            /* in zephyr/dts/xtensa/espressif/esp32/esp32_common.dtsi:399 */
			clocks = < &clock 0x18 >;            /* in zephyr/dts/xtensa/espressif/esp32/esp32_common.dtsi:400 */
			status = "okay";                     /* in zephyr/boards/espressif/esp32_devkitc/esp32_devkitc_procpu.dts:136 */
		};

		/* node '/soc/watchdog@3ff5f048' defined in zephyr/dts/xtensa/espressif/esp32/esp32_common.dtsi:404 */
		wdt0: watchdog@3ff5f048 {
			compatible = "espressif,esp32-watchdog"; /* in zephyr/dts/xtensa/espressif/esp32/esp32_common.dtsi:405 */
			reg = < 0x3ff5f048 0x20 >;               /* in zephyr/dts/xtensa/espressif/esp32/esp32_common.dtsi:406 */
			interrupts = < 0x10 0x0 0x0 >;           /* in zephyr/dts/xtensa/espressif/esp32/esp32_common.dtsi:407 */
			interrupt-parent = < &intc >;            /* in zephyr/dts/xtensa/espressif/esp32/esp32_common.dtsi:408 */
			clocks = < &clock 0x8 >;                 /* in zephyr/dts/xtensa/espressif/esp32/esp32_common.dtsi:409 */
			status = "okay";                         /* in zephyr/dts/xtensa/espressif/esp32/esp32_common.dtsi:410 */
		};

		/* node '/soc/watchdog@3ff60048' defined in zephyr/dts/xtensa/espressif/esp32/esp32_common.dtsi:413 */
		wdt1: watchdog@3ff60048 {
			compatible = "espressif,esp32-watchdog"; /* in zephyr/dts/xtensa/espressif/esp32/esp32_common.dtsi:414 */
			reg = < 0x3ff60048 0x20 >;               /* in zephyr/dts/xtensa/espressif/esp32/esp32_common.dtsi:415 */
			interrupts = < 0x14 0x0 0x0 >;           /* in zephyr/dts/xtensa/espressif/esp32/esp32_common.dtsi:416 */
			interrupt-parent = < &intc >;            /* in zephyr/dts/xtensa/espressif/esp32/esp32_common.dtsi:417 */
			clocks = < &clock 0x9 >;                 /* in zephyr/dts/xtensa/espressif/esp32/esp32_common.dtsi:418 */
			status = "disabled";                     /* in zephyr/dts/xtensa/espressif/esp32/esp32_common.dtsi:419 */
		};

		/* node '/soc/spi@3ff64000' defined in zephyr/dts/xtensa/espressif/esp32/esp32_common.dtsi:422 */
		spi2: spi@3ff64000 {
			compatible = "espressif,esp32-spi"; /* in zephyr/dts/xtensa/espressif/esp32/esp32_common.dtsi:423 */
			reg = < 0x3ff64000 0x1000 >;        /* in zephyr/dts/xtensa/espressif/esp32/esp32_common.dtsi:424 */
			interrupts = < 0x1e 0x0 0x0 >;      /* in zephyr/dts/xtensa/espressif/esp32/esp32_common.dtsi:425 */
			interrupt-parent = < &intc >;       /* in zephyr/dts/xtensa/espressif/esp32/esp32_common.dtsi:426 */
			clocks = < &clock 0x11 >;           /* in zephyr/dts/xtensa/espressif/esp32/esp32_common.dtsi:427 */
			dma-clk = < 0x13 >;                 /* in zephyr/dts/xtensa/espressif/esp32/esp32_common.dtsi:428 */
			dma-host = < 0x0 >;                 /* in zephyr/dts/xtensa/espressif/esp32/esp32_common.dtsi:429 */
			#address-cells = < 0x1 >;           /* in zephyr/boards/espressif/esp32_devkitc/esp32_devkitc_procpu.dts:104 */
			#size-cells = < 0x0 >;              /* in zephyr/boards/espressif/esp32_devkitc/esp32_devkitc_procpu.dts:105 */
			status = "okay";                    /* in zephyr/boards/espressif/esp32_devkitc/esp32_devkitc_procpu.dts:106 */
			pinctrl-0 = < &spim2_default >;     /* in zephyr/boards/espressif/esp32_devkitc/esp32_devkitc_procpu.dts:107 */
			pinctrl-names = "default";          /* in zephyr/boards/espressif/esp32_devkitc/esp32_devkitc_procpu.dts:108 */
		};

		/* node '/soc/spi@3ff65000' defined in zephyr/dts/xtensa/espressif/esp32/esp32_common.dtsi:433 */
		spi3: spi@3ff65000 {
			compatible = "espressif,esp32-spi"; /* in zephyr/dts/xtensa/espressif/esp32/esp32_common.dtsi:434 */
			reg = < 0x3ff65000 0x1000 >;        /* in zephyr/dts/xtensa/espressif/esp32/esp32_common.dtsi:435 */
			interrupts = < 0x1f 0x0 0x0 >;      /* in zephyr/dts/xtensa/espressif/esp32/esp32_common.dtsi:436 */
			interrupt-parent = < &intc >;       /* in zephyr/dts/xtensa/espressif/esp32/esp32_common.dtsi:437 */
			clocks = < &clock 0x12 >;           /* in zephyr/dts/xtensa/espressif/esp32/esp32_common.dtsi:438 */
			dma-clk = < 0x13 >;                 /* in zephyr/dts/xtensa/espressif/esp32/esp32_common.dtsi:439 */
			dma-host = < 0x1 >;                 /* in zephyr/dts/xtensa/espressif/esp32/esp32_common.dtsi:440 */
			#address-cells = < 0x1 >;           /* in zephyr/boards/espressif/esp32_devkitc/esp32_devkitc_procpu.dts:112 */
			#size-cells = < 0x0 >;              /* in zephyr/boards/espressif/esp32_devkitc/esp32_devkitc_procpu.dts:113 */
			status = "okay";                    /* in zephyr/boards/espressif/esp32_devkitc/esp32_devkitc_procpu.dts:114 */
			pinctrl-0 = < &spim3_default >;     /* in zephyr/boards/espressif/esp32_devkitc/esp32_devkitc_procpu.dts:115 */
			pinctrl-names = "default";          /* in zephyr/boards/espressif/esp32_devkitc/esp32_devkitc_procpu.dts:116 */
		};

		/* node '/soc/can@3ff6b000' defined in zephyr/dts/xtensa/espressif/esp32/esp32_common.dtsi:444 */
		twai: can@3ff6b000 {
			compatible = "espressif,esp32-twai"; /* in zephyr/dts/xtensa/espressif/esp32/esp32_common.dtsi:445 */
			reg = < 0x3ff6b000 0x1000 >;         /* in zephyr/dts/xtensa/espressif/esp32/esp32_common.dtsi:446 */
			interrupts = < 0x2d 0x0 0x0 >;       /* in zephyr/dts/xtensa/espressif/esp32/esp32_common.dtsi:447 */
			interrupt-parent = < &intc >;        /* in zephyr/dts/xtensa/espressif/esp32/esp32_common.dtsi:448 */
			clocks = < &clock 0x16 >;            /* in zephyr/dts/xtensa/espressif/esp32/esp32_common.dtsi:449 */
			status = "disabled";                 /* in zephyr/dts/xtensa/espressif/esp32/esp32_common.dtsi:450 */
		};

		/* node '/soc/counter@3ff5f000' defined in zephyr/dts/xtensa/espressif/esp32/esp32_common.dtsi:453 */
		timer0: counter@3ff5f000 {
			compatible = "espressif,esp32-timer"; /* in zephyr/dts/xtensa/espressif/esp32/esp32_common.dtsi:454 */
			reg = < 0x3ff5f000 0x1000 >;          /* in zephyr/dts/xtensa/espressif/esp32/esp32_common.dtsi:455 */
			clocks = < &clock 0x8 >;              /* in zephyr/dts/xtensa/espressif/esp32/esp32_common.dtsi:456 */
			group = < 0x0 >;                      /* in zephyr/dts/xtensa/espressif/esp32/esp32_common.dtsi:457 */
			index = < 0x0 >;                      /* in zephyr/dts/xtensa/espressif/esp32/esp32_common.dtsi:458 */
			interrupts = < 0xe 0x0 0x0 >;         /* in zephyr/dts/xtensa/espressif/esp32/esp32_common.dtsi:459 */
			interrupt-parent = < &intc >;         /* in zephyr/dts/xtensa/espressif/esp32/esp32_common.dtsi:460 */
			status = "disabled";                  /* in zephyr/boards/espressif/esp32_devkitc/esp32_devkitc_procpu.dts:120 */

			/* node '/soc/counter@3ff5f000/counter' defined in zephyr/dts/xtensa/espressif/esp32/esp32_common.dtsi:463 */
			counter {
				compatible = "espressif,esp32-counter"; /* in zephyr/dts/xtensa/espressif/esp32/esp32_common.dtsi:464 */
				status = "disabled";                    /* in zephyr/dts/xtensa/espressif/esp32/esp32_common.dtsi:465 */
			};
		};

		/* node '/soc/counter@3ff5f024' defined in zephyr/dts/xtensa/espressif/esp32/esp32_common.dtsi:469 */
		timer1: counter@3ff5f024 {
			compatible = "espressif,esp32-timer"; /* in zephyr/dts/xtensa/espressif/esp32/esp32_common.dtsi:470 */
			reg = < 0x3ff5f024 0x1000 >;          /* in zephyr/dts/xtensa/espressif/esp32/esp32_common.dtsi:471 */
			clocks = < &clock 0x8 >;              /* in zephyr/dts/xtensa/espressif/esp32/esp32_common.dtsi:472 */
			group = < 0x0 >;                      /* in zephyr/dts/xtensa/espressif/esp32/esp32_common.dtsi:473 */
			index = < 0x1 >;                      /* in zephyr/dts/xtensa/espressif/esp32/esp32_common.dtsi:474 */
			interrupts = < 0xf 0x0 0x0 >;         /* in zephyr/dts/xtensa/espressif/esp32/esp32_common.dtsi:475 */
			interrupt-parent = < &intc >;         /* in zephyr/dts/xtensa/espressif/esp32/esp32_common.dtsi:476 */
			status = "disabled";                  /* in zephyr/boards/espressif/esp32_devkitc/esp32_devkitc_procpu.dts:124 */

			/* node '/soc/counter@3ff5f024/counter' defined in zephyr/dts/xtensa/espressif/esp32/esp32_common.dtsi:479 */
			counter {
				compatible = "espressif,esp32-counter"; /* in zephyr/dts/xtensa/espressif/esp32/esp32_common.dtsi:480 */
				status = "disabled";                    /* in zephyr/dts/xtensa/espressif/esp32/esp32_common.dtsi:481 */
			};
		};

		/* node '/soc/counter@3ff60000' defined in zephyr/dts/xtensa/espressif/esp32/esp32_common.dtsi:485 */
		timer2: counter@3ff60000 {
			compatible = "espressif,esp32-timer"; /* in zephyr/dts/xtensa/espressif/esp32/esp32_common.dtsi:486 */
			reg = < 0x3ff60000 0x1000 >;          /* in zephyr/dts/xtensa/espressif/esp32/esp32_common.dtsi:487 */
			clocks = < &clock 0x9 >;              /* in zephyr/dts/xtensa/espressif/esp32/esp32_common.dtsi:488 */
			group = < 0x1 >;                      /* in zephyr/dts/xtensa/espressif/esp32/esp32_common.dtsi:489 */
			index = < 0x0 >;                      /* in zephyr/dts/xtensa/espressif/esp32/esp32_common.dtsi:490 */
			interrupts = < 0x12 0x0 0x0 >;        /* in zephyr/dts/xtensa/espressif/esp32/esp32_common.dtsi:491 */
			interrupt-parent = < &intc >;         /* in zephyr/dts/xtensa/espressif/esp32/esp32_common.dtsi:492 */
			status = "disabled";                  /* in zephyr/boards/espressif/esp32_devkitc/esp32_devkitc_procpu.dts:128 */

			/* node '/soc/counter@3ff60000/counter' defined in zephyr/dts/xtensa/espressif/esp32/esp32_common.dtsi:495 */
			counter {
				compatible = "espressif,esp32-counter"; /* in zephyr/dts/xtensa/espressif/esp32/esp32_common.dtsi:496 */
				status = "disabled";                    /* in zephyr/dts/xtensa/espressif/esp32/esp32_common.dtsi:497 */
			};
		};

		/* node '/soc/counter@3ff60024' defined in zephyr/dts/xtensa/espressif/esp32/esp32_common.dtsi:501 */
		timer3: counter@3ff60024 {
			compatible = "espressif,esp32-timer"; /* in zephyr/dts/xtensa/espressif/esp32/esp32_common.dtsi:502 */
			reg = < 0x3ff60024 0x1000 >;          /* in zephyr/dts/xtensa/espressif/esp32/esp32_common.dtsi:503 */
			clocks = < &clock 0x9 >;              /* in zephyr/dts/xtensa/espressif/esp32/esp32_common.dtsi:504 */
			group = < 0x1 >;                      /* in zephyr/dts/xtensa/espressif/esp32/esp32_common.dtsi:505 */
			index = < 0x1 >;                      /* in zephyr/dts/xtensa/espressif/esp32/esp32_common.dtsi:506 */
			interrupts = < 0x13 0x0 0x0 >;        /* in zephyr/dts/xtensa/espressif/esp32/esp32_common.dtsi:507 */
			interrupt-parent = < &intc >;         /* in zephyr/dts/xtensa/espressif/esp32/esp32_common.dtsi:508 */
			status = "disabled";                  /* in zephyr/boards/espressif/esp32_devkitc/esp32_devkitc_procpu.dts:132 */

			/* node '/soc/counter@3ff60024/counter' defined in zephyr/dts/xtensa/espressif/esp32/esp32_common.dtsi:511 */
			counter {
				compatible = "espressif,esp32-counter"; /* in zephyr/dts/xtensa/espressif/esp32/esp32_common.dtsi:512 */
				status = "disabled";                    /* in zephyr/dts/xtensa/espressif/esp32/esp32_common.dtsi:513 */
			};
		};

		/* node '/soc/dac@3ff48800' defined in zephyr/dts/xtensa/espressif/esp32/esp32_common.dtsi:517 */
		dac: dac@3ff48800 {
			compatible = "espressif,esp32-dac"; /* in zephyr/dts/xtensa/espressif/esp32/esp32_common.dtsi:518 */
			reg = < 0x3ff48800 0x100 >;         /* in zephyr/dts/xtensa/espressif/esp32/esp32_common.dtsi:519 */
			interrupts = < 0x2e 0x0 0x0 >;      /* in zephyr/dts/xtensa/espressif/esp32/esp32_common.dtsi:520 */
			interrupt-parent = < &intc >;       /* in zephyr/dts/xtensa/espressif/esp32/esp32_common.dtsi:521 */
			clocks = < &clock 0x21 >;           /* in zephyr/dts/xtensa/espressif/esp32/esp32_common.dtsi:522 */
			#io-channel-cells = < 0x1 >;        /* in zephyr/dts/xtensa/espressif/esp32/esp32_common.dtsi:523 */
			status = "disabled";                /* in zephyr/dts/xtensa/espressif/esp32/esp32_common.dtsi:524 */
		};

		/* node '/soc/adc@3ff48800' defined in zephyr/dts/xtensa/espressif/esp32/esp32_common.dtsi:527 */
		adc0: adc@3ff48800 {
			compatible = "espressif,esp32-adc"; /* in zephyr/dts/xtensa/espressif/esp32/esp32_common.dtsi:528 */
			reg = < 0x3ff48800 0xa >;           /* in zephyr/dts/xtensa/espressif/esp32/esp32_common.dtsi:529 */
			clocks = < &clock 0x21 >;           /* in zephyr/dts/xtensa/espressif/esp32/esp32_common.dtsi:530 */
			interrupt-parent = < &intc >;       /* in zephyr/dts/xtensa/espressif/esp32/esp32_common.dtsi:531 */
			unit = < 0x1 >;                     /* in zephyr/dts/xtensa/espressif/esp32/esp32_common.dtsi:532 */
			channel-count = < 0x8 >;            /* in zephyr/dts/xtensa/espressif/esp32/esp32_common.dtsi:533 */
			#io-channel-cells = < 0x1 >;        /* in zephyr/dts/xtensa/espressif/esp32/esp32_common.dtsi:534 */
			status = "disabled";                /* in zephyr/dts/xtensa/espressif/esp32/esp32_common.dtsi:535 */
		};

		/* node '/soc/adc@3ff48890' defined in zephyr/dts/xtensa/espressif/esp32/esp32_common.dtsi:538 */
		adc1: adc@3ff48890 {
			compatible = "espressif,esp32-adc"; /* in zephyr/dts/xtensa/espressif/esp32/esp32_common.dtsi:539 */
			reg = < 0x3ff48890 0xa >;           /* in zephyr/dts/xtensa/espressif/esp32/esp32_common.dtsi:540 */
			clocks = < &clock 0x21 >;           /* in zephyr/dts/xtensa/espressif/esp32/esp32_common.dtsi:541 */
			unit = < 0x2 >;                     /* in zephyr/dts/xtensa/espressif/esp32/esp32_common.dtsi:542 */
			channel-count = < 0xa >;            /* in zephyr/dts/xtensa/espressif/esp32/esp32_common.dtsi:543 */
			#io-channel-cells = < 0x1 >;        /* in zephyr/dts/xtensa/espressif/esp32/esp32_common.dtsi:544 */
			status = "disabled";                /* in zephyr/dts/xtensa/espressif/esp32/esp32_common.dtsi:545 */
		};

		/* node '/soc/sdhc@3ff68000' defined in zephyr/dts/xtensa/espressif/esp32/esp32_common.dtsi:548 */
		sdhc: sdhc@3ff68000 {
			compatible = "espressif,esp32-sdhc"; /* in zephyr/dts/xtensa/espressif/esp32/esp32_common.dtsi:549 */
			reg = < 0x3ff68000 0x1000 >;         /* in zephyr/dts/xtensa/espressif/esp32/esp32_common.dtsi:550 */
			interrupts = < 0x25 0x0 0x0 >;       /* in zephyr/dts/xtensa/espressif/esp32/esp32_common.dtsi:551 */
			interrupt-parent = < &intc >;        /* in zephyr/dts/xtensa/espressif/esp32/esp32_common.dtsi:552 */
			clocks = < &clock 0x14 >;            /* in zephyr/dts/xtensa/espressif/esp32/esp32_common.dtsi:553 */
			#address-cells = < 0x1 >;            /* in zephyr/dts/xtensa/espressif/esp32/esp32_common.dtsi:554 */
			#size-cells = < 0x0 >;               /* in zephyr/dts/xtensa/espressif/esp32/esp32_common.dtsi:555 */

			/* node '/soc/sdhc@3ff68000/sdhc@0' defined in zephyr/dts/xtensa/espressif/esp32/esp32_common.dtsi:557 */
			sdhc0: sdhc@0 {
				compatible = "espressif,esp32-sdhc-slot"; /* in zephyr/dts/xtensa/espressif/esp32/esp32_common.dtsi:558 */
				reg = < 0x0 >;                            /* in zephyr/dts/xtensa/espressif/esp32/esp32_common.dtsi:559 */
				status = "disabled";                      /* in zephyr/dts/xtensa/espressif/esp32/esp32_common.dtsi:560 */
			};

			/* node '/soc/sdhc@3ff68000/sdhc@1' defined in zephyr/dts/xtensa/espressif/esp32/esp32_common.dtsi:563 */
			sdhc1: sdhc@1 {
				compatible = "espressif,esp32-sdhc-slot"; /* in zephyr/dts/xtensa/espressif/esp32/esp32_common.dtsi:564 */
				reg = < 0x1 >;                            /* in zephyr/dts/xtensa/espressif/esp32/esp32_common.dtsi:565 */
				status = "disabled";                      /* in zephyr/dts/xtensa/espressif/esp32/esp32_common.dtsi:566 */
			};
		};

		/* node '/soc/sha@3ff03000' defined in zephyr/dts/xtensa/espressif/esp32/esp32_common.dtsi:570 */
		sha: sha@3ff03000 {
			compatible = "espressif,esp32-sha"; /* in zephyr/dts/xtensa/espressif/esp32/esp32_common.dtsi:571 */
			reg = < 0x3ff03000 0x100 >;         /* in zephyr/dts/xtensa/espressif/esp32/esp32_common.dtsi:572 */
			clocks = < &clock 0x1f >;           /* in zephyr/dts/xtensa/espressif/esp32/esp32_common.dtsi:573 */
			status = "okay";                    /* in zephyr/dts/xtensa/espressif/esp32/esp32_common.dtsi:574 */
		};

		/* node '/soc/aes@3ff01000' defined in zephyr/dts/xtensa/espressif/esp32/esp32_common.dtsi:577 */
		aes: aes@3ff01000 {
			compatible = "espressif,esp32-aes"; /* in zephyr/dts/xtensa/espressif/esp32/esp32_common.dtsi:578 */
			reg = < 0x3ff01000 0x1000 >;        /* in zephyr/dts/xtensa/espressif/esp32/esp32_common.dtsi:579 */
			clocks = < &clock 0x1e >;           /* in zephyr/dts/xtensa/espressif/esp32/esp32_common.dtsi:580 */
			status = "okay";                    /* in zephyr/dts/xtensa/espressif/esp32/esp32_common.dtsi:581 */
		};
	};

	/* node '/cpus' defined in zephyr/dts/xtensa/espressif/esp32/esp32_common.dtsi:26 */
	cpus {
		#address-cells = < 0x1 >; /* in zephyr/dts/xtensa/espressif/esp32/esp32_common.dtsi:27 */
		#size-cells = < 0x0 >;    /* in zephyr/dts/xtensa/espressif/esp32/esp32_common.dtsi:28 */

		/* node '/cpus/cpu@0' defined in zephyr/dts/xtensa/espressif/esp32/esp32_common.dtsi:30 */
		cpu0: cpu@0 {
			device_type = "cpu";                             /* in zephyr/dts/xtensa/espressif/esp32/esp32_common.dtsi:31 */
			compatible = "espressif,xtensa-lx6";             /* in zephyr/dts/xtensa/espressif/esp32/esp32_common.dtsi:32 */
			reg = < 0x0 >;                                   /* in zephyr/dts/xtensa/espressif/esp32/esp32_common.dtsi:33 */
			cpu-power-states = < &light_sleep &deep_sleep >; /* in zephyr/dts/xtensa/espressif/esp32/esp32_common.dtsi:34 */
			clock-source = < 0x1 >;                          /* in zephyr/dts/xtensa/espressif/esp32/esp32_common.dtsi:35 */
			clock-frequency = < 0xe4e1c00 >;                 /* in zephyr/dts/xtensa/espressif/esp32/esp32_common.dtsi:36 */
			xtal-freq = < 0x2625a00 >;                       /* in zephyr/dts/xtensa/espressif/esp32/esp32_common.dtsi:37 */
		};

		/* node '/cpus/cpu@1' defined in zephyr/dts/xtensa/espressif/esp32/esp32_common.dtsi:40 */
		cpu1: cpu@1 {
			device_type = "cpu";                 /* in zephyr/dts/xtensa/espressif/esp32/esp32_common.dtsi:41 */
			compatible = "espressif,xtensa-lx6"; /* in zephyr/dts/xtensa/espressif/esp32/esp32_common.dtsi:42 */
			reg = < 0x1 >;                       /* in zephyr/dts/xtensa/espressif/esp32/esp32_common.dtsi:43 */
			clock-source = < 0x1 >;              /* in zephyr/dts/xtensa/espressif/esp32/esp32_common.dtsi:44 */
			clock-frequency = < 0xe4e1c00 >;     /* in zephyr/dts/xtensa/espressif/esp32/esp32_common.dtsi:45 */
			xtal-freq = < 0x2625a00 >;           /* in zephyr/dts/xtensa/espressif/esp32/esp32_common.dtsi:46 */
		};

		/* node '/cpus/power-states' defined in zephyr/dts/xtensa/espressif/esp32/esp32_common.dtsi:49 */
		power-states {

			/* node '/cpus/power-states/light_sleep' defined in zephyr/dts/xtensa/espressif/esp32/esp32_common.dtsi:50 */
			light_sleep: light_sleep {
				compatible = "zephyr,power-state"; /* in zephyr/dts/xtensa/espressif/esp32/esp32_common.dtsi:51 */
				power-state-name = "standby";      /* in zephyr/dts/xtensa/espressif/esp32/esp32_common.dtsi:52 */
				min-residency-us = < 0xc8 >;       /* in zephyr/dts/xtensa/espressif/esp32/esp32_common.dtsi:53 */
				exit-latency-us = < 0x3c >;        /* in zephyr/dts/xtensa/espressif/esp32/esp32_common.dtsi:54 */
				phandle = < 0xe >;                 /* in zephyr/dts/xtensa/espressif/esp32/esp32_common.dtsi:34 */
			};

			/* node '/cpus/power-states/deep_sleep' defined in zephyr/dts/xtensa/espressif/esp32/esp32_common.dtsi:57 */
			deep_sleep: deep_sleep {
				compatible = "zephyr,power-state"; /* in zephyr/dts/xtensa/espressif/esp32/esp32_common.dtsi:58 */
				power-state-name = "soft-off";     /* in zephyr/dts/xtensa/espressif/esp32/esp32_common.dtsi:59 */
				min-residency-us = < 0x7d0 >;      /* in zephyr/dts/xtensa/espressif/esp32/esp32_common.dtsi:60 */
				exit-latency-us = < 0xd4 >;        /* in zephyr/dts/xtensa/espressif/esp32/esp32_common.dtsi:61 */
				phandle = < 0xf >;                 /* in zephyr/dts/xtensa/espressif/esp32/esp32_common.dtsi:34 */
			};
		};
	};

	/* node '/wifi' defined in zephyr/dts/xtensa/espressif/esp32/esp32_common.dtsi:66 */
	wifi: wifi {
		compatible = "espressif,esp32-wifi"; /* in zephyr/dts/xtensa/espressif/esp32/esp32_common.dtsi:67 */
		status = "okay";                     /* in zephyr/boards/espressif/esp32_devkitc/esp32_devkitc_procpu.dts:144 */
	};

	/* node '/esp32_bt_hci' defined in zephyr/dts/xtensa/espressif/esp32/esp32_common.dtsi:71 */
	esp32_bt_hci: esp32_bt_hci {
		compatible = "espressif,esp32-bt-hci"; /* in zephyr/dts/xtensa/espressif/esp32/esp32_common.dtsi:72 */
		status = "okay";                       /* in zephyr/boards/espressif/esp32_devkitc/esp32_devkitc_procpu.dts:140 */
	};

	/* node '/eth' defined in zephyr/dts/xtensa/espressif/esp32/esp32_common.dtsi:76 */
	eth: eth {
		compatible = "espressif,esp32-eth"; /* in zephyr/dts/xtensa/espressif/esp32/esp32_common.dtsi:77 */
		interrupts = < 0x26 0x0 0x0 >;      /* in zephyr/dts/xtensa/espressif/esp32/esp32_common.dtsi:78 */
		interrupt-parent = < &intc >;       /* in zephyr/dts/xtensa/espressif/esp32/esp32_common.dtsi:79 */
		clocks = < &clock 0x17 >;           /* in zephyr/dts/xtensa/espressif/esp32/esp32_common.dtsi:80 */
		status = "disabled";                /* in zephyr/dts/xtensa/espressif/esp32/esp32_common.dtsi:81 */
	};

	/* node '/mdio' defined in zephyr/dts/xtensa/espressif/esp32/esp32_common.dtsi:84 */
	mdio: mdio {
		compatible = "espressif,esp32-mdio"; /* in zephyr/dts/xtensa/espressif/esp32/esp32_common.dtsi:85 */
		clocks = < &clock 0x17 >;            /* in zephyr/dts/xtensa/espressif/esp32/esp32_common.dtsi:86 */
		status = "disabled";                 /* in zephyr/dts/xtensa/espressif/esp32/esp32_common.dtsi:87 */
		#address-cells = < 0x1 >;            /* in zephyr/dts/xtensa/espressif/esp32/esp32_common.dtsi:88 */
		#size-cells = < 0x0 >;               /* in zephyr/dts/xtensa/espressif/esp32/esp32_common.dtsi:89 */
	};

	/* node '/pin-controller' defined in zephyr/dts/xtensa/espressif/esp32/esp32_common.dtsi:92 */
	pinctrl: pin-controller {
		compatible = "espressif,esp32-pinctrl"; /* in zephyr/dts/xtensa/espressif/esp32/esp32_common.dtsi:93 */
		status = "okay";                        /* in zephyr/dts/xtensa/espressif/esp32/esp32_common.dtsi:94 */

		/* node '/pin-controller/uart0_default' defined in zephyr/boards/espressif/esp32_devkitc/esp32_devkitc-pinctrl.dtsi:12 */
		uart0_default: uart0_default {
			phandle = < 0x4 >; /* in zephyr/boards/espressif/esp32_devkitc/esp32_devkitc_procpu.dts:48 */

			/* node '/pin-controller/uart0_default/group1' defined in zephyr/boards/espressif/esp32_devkitc/esp32_devkitc-pinctrl.dtsi:13 */
			group1 {
				pinmux = < 0x77fc1 >; /* in zephyr/boards/espressif/esp32_devkitc/esp32_devkitc-pinctrl.dtsi:14 */
				output-high;          /* in zephyr/boards/espressif/esp32_devkitc/esp32_devkitc-pinctrl.dtsi:15 */
			};

			/* node '/pin-controller/uart0_default/group2' defined in zephyr/boards/espressif/esp32_devkitc/esp32_devkitc-pinctrl.dtsi:18 */
			group2 {
				pinmux = < 0xff8383 >; /* in zephyr/boards/espressif/esp32_devkitc/esp32_devkitc-pinctrl.dtsi:19 */
				bias-pull-up;          /* in zephyr/boards/espressif/esp32_devkitc/esp32_devkitc-pinctrl.dtsi:20 */
			};
		};

		/* node '/pin-controller/uart1_default' defined in zephyr/boards/espressif/esp32_devkitc/esp32_devkitc-pinctrl.dtsi:24 */
		uart1_default: uart1_default {
			phandle = < 0x5 >; /* in zephyr/boards/espressif/esp32_devkitc/esp32_devkitc_procpu.dts:54 */

			/* node '/pin-controller/uart1_default/group1' defined in zephyr/boards/espressif/esp32_devkitc/esp32_devkitc-pinctrl.dtsi:25 */
			group1 {
				pinmux = < 0x8ffca >; /* in zephyr/boards/espressif/esp32_devkitc/esp32_devkitc-pinctrl.dtsi:26 */
			};

			/* node '/pin-controller/uart1_default/group2' defined in zephyr/boards/espressif/esp32_devkitc/esp32_devkitc-pinctrl.dtsi:29 */
			group2 {
				pinmux = < 0xff8449 >; /* in zephyr/boards/espressif/esp32_devkitc/esp32_devkitc-pinctrl.dtsi:30 */
				bias-pull-up;          /* in zephyr/boards/espressif/esp32_devkitc/esp32_devkitc-pinctrl.dtsi:31 */
			};
		};

		/* node '/pin-controller/uart2_default' defined in zephyr/boards/espressif/esp32_devkitc/esp32_devkitc-pinctrl.dtsi:35 */
		uart2_default: uart2_default {
			phandle = < 0x6 >; /* in zephyr/boards/espressif/esp32_devkitc/esp32_devkitc_procpu.dts:60 */

			/* node '/pin-controller/uart2_default/group1' defined in zephyr/boards/espressif/esp32_devkitc/esp32_devkitc-pinctrl.dtsi:36 */
			group1 {
				pinmux = < 0x637fd1 >; /* in zephyr/boards/espressif/esp32_devkitc/esp32_devkitc-pinctrl.dtsi:37 */
			};

			/* node '/pin-controller/uart2_default/group2' defined in zephyr/boards/espressif/esp32_devkitc/esp32_devkitc-pinctrl.dtsi:40 */
			group2 {
				pinmux = < 0xffb190 >; /* in zephyr/boards/espressif/esp32_devkitc/esp32_devkitc-pinctrl.dtsi:41 */
				bias-pull-up;          /* in zephyr/boards/espressif/esp32_devkitc/esp32_devkitc-pinctrl.dtsi:42 */
			};
		};

		/* node '/pin-controller/spim2_default' defined in zephyr/boards/espressif/esp32_devkitc/esp32_devkitc-pinctrl.dtsi:46 */
		spim2_default: spim2_default {
			phandle = < 0xc >; /* in zephyr/boards/espressif/esp32_devkitc/esp32_devkitc_procpu.dts:107 */

			/* node '/pin-controller/spim2_default/group1' defined in zephyr/boards/espressif/esp32_devkitc/esp32_devkitc-pinctrl.dtsi:47 */
			group1 {
				pinmux = < 0xff824c >,
				         < 0x47fce >,
				         < 0x5ffcf >;  /* in zephyr/boards/espressif/esp32_devkitc/esp32_devkitc-pinctrl.dtsi:48 */
			};

			/* node '/pin-controller/spim2_default/group2' defined in zephyr/boards/espressif/esp32_devkitc/esp32_devkitc-pinctrl.dtsi:53 */
			group2 {
				pinmux = < 0x57fcd >; /* in zephyr/boards/espressif/esp32_devkitc/esp32_devkitc-pinctrl.dtsi:54 */
				output-low;           /* in zephyr/boards/espressif/esp32_devkitc/esp32_devkitc-pinctrl.dtsi:55 */
			};
		};

		/* node '/pin-controller/spim3_default' defined in zephyr/boards/espressif/esp32_devkitc/esp32_devkitc-pinctrl.dtsi:59 */
		spim3_default: spim3_default {
			phandle = < 0xd >; /* in zephyr/boards/espressif/esp32_devkitc/esp32_devkitc_procpu.dts:115 */

			/* node '/pin-controller/spim3_default/group1' defined in zephyr/boards/espressif/esp32_devkitc/esp32_devkitc-pinctrl.dtsi:60 */
			group1 {
				pinmux = < 0xff9013 >,
				         < 0x1fffd2 >,
				         < 0x227fc5 >; /* in zephyr/boards/espressif/esp32_devkitc/esp32_devkitc-pinctrl.dtsi:61 */
			};

			/* node '/pin-controller/spim3_default/group2' defined in zephyr/boards/espressif/esp32_devkitc/esp32_devkitc-pinctrl.dtsi:66 */
			group2 {
				pinmux = < 0x20ffd7 >; /* in zephyr/boards/espressif/esp32_devkitc/esp32_devkitc-pinctrl.dtsi:67 */
				output-low;            /* in zephyr/boards/espressif/esp32_devkitc/esp32_devkitc-pinctrl.dtsi:68 */
			};
		};

		/* node '/pin-controller/i2c0_default' defined in zephyr/boards/espressif/esp32_devkitc/esp32_devkitc-pinctrl.dtsi:72 */
		i2c0_default: i2c0_default {
			phandle = < 0x9 >; /* in zephyr/boards/espressif/esp32_devkitc/esp32_devkitc_procpu.dts:89 */

			/* node '/pin-controller/i2c0_default/group1' defined in zephyr/boards/espressif/esp32_devkitc/esp32_devkitc-pinctrl.dtsi:73 */
			group1 {
				pinmux = < 0xf0795 >,
				         < 0xe8756 >; /* in zephyr/boards/espressif/esp32_devkitc/esp32_devkitc-pinctrl.dtsi:74 */
				bias-pull-up;         /* in zephyr/boards/espressif/esp32_devkitc/esp32_devkitc-pinctrl.dtsi:76 */
				drive-open-drain;     /* in zephyr/boards/espressif/esp32_devkitc/esp32_devkitc-pinctrl.dtsi:77 */
				output-high;          /* in zephyr/boards/espressif/esp32_devkitc/esp32_devkitc-pinctrl.dtsi:78 */
			};
		};

		/* node '/pin-controller/i2s0_default' defined in zephyr/boards/espressif/esp32_devkitc/esp32_devkitc-pinctrl.dtsi:82 */
		i2s0_default: i2s0_default {
			phandle = < 0xa >; /* in zephyr/boards/espressif/esp32_devkitc/esp32_devkitc_procpu.dts:94 */

			/* node '/pin-controller/i2s0_default/group1' defined in zephyr/boards/espressif/esp32_devkitc/esp32_devkitc-pinctrl.dtsi:83 */
			group1 {
				pinmux = < 0xc8661 >,
				         < 0xb85e0 >,
				         < 0x51ffd9 >,
				         < 0xffa6d1 >; /* in zephyr/boards/espressif/esp32_devkitc/esp32_devkitc-pinctrl.dtsi:84 */
			};
		};

		/* node '/pin-controller/i2s1_default' defined in zephyr/boards/espressif/esp32_devkitc/esp32_devkitc-pinctrl.dtsi:91 */
		i2s1_default: i2s1_default {
			phandle = < 0xb >; /* in zephyr/boards/espressif/esp32_devkitc/esp32_devkitc_procpu.dts:99 */

			/* node '/pin-controller/i2s1_default/group1' defined in zephyr/boards/espressif/esp32_devkitc/esp32_devkitc-pinctrl.dtsi:92 */
			group1 {
				pinmux = < 0xd0685 >,
				         < 0xc0612 >,
				         < 0x5effd3 >,
				         < 0xffad4b >; /* in zephyr/boards/espressif/esp32_devkitc/esp32_devkitc-pinctrl.dtsi:93 */
			};
		};
	};

	/* node '/clock' defined in zephyr/dts/xtensa/espressif/esp32/esp32_common.dtsi:97 */
	clock: clock {
		compatible = "espressif,esp32-clock"; /* in zephyr/dts/xtensa/espressif/esp32/esp32_common.dtsi:98 */
		fast-clk-src = < 0x1 >;               /* in zephyr/dts/xtensa/espressif/esp32/esp32_common.dtsi:99 */
		slow-clk-src = < 0x0 >;               /* in zephyr/dts/xtensa/espressif/esp32/esp32_common.dtsi:100 */
		#clock-cells = < 0x1 >;               /* in zephyr/dts/xtensa/espressif/esp32/esp32_common.dtsi:101 */
		status = "okay";                      /* in zephyr/dts/xtensa/espressif/esp32/esp32_common.dtsi:102 */
		phandle = < 0x3 >;                    /* in zephyr/dts/xtensa/espressif/esp32/esp32_common.dtsi:204 */
	};

	/* node '/buttons' defined in zephyr/boards/espressif/esp32_devkitc/esp32_devkitc_procpu.dts:25 */
	buttons {
		compatible = "gpio-keys"; /* in zephyr/trabalho/app.overlay:3 */

		/* node '/buttons/button_0' defined in zephyr/boards/espressif/esp32_devkitc/esp32_devkitc_procpu.dts:28 */
		button0: button_0 {
			gpios = < &gpio0 0x0 0x11 >; /* in zephyr/boards/espressif/esp32_devkitc/esp32_devkitc_procpu.dts:29 */
			label = "BOOT Button";       /* in zephyr/boards/espressif/esp32_devkitc/esp32_devkitc_procpu.dts:30 */
			zephyr,code = < 0xb >;       /* in zephyr/boards/espressif/esp32_devkitc/esp32_devkitc_procpu.dts:31 */
		};

		/* node '/buttons/lo_plus' defined in zephyr/trabalho/app.overlay:4 */
		lo_p: lo_plus {
			gpios = < &gpio0 0x1a 0x10 >; /* in zephyr/trabalho/app.overlay:5 */
			label = "Lead Off Positive";  /* in zephyr/trabalho/app.overlay:6 */
		};

		/* node '/buttons/lo_minus' defined in zephyr/trabalho/app.overlay:8 */
		lo_n: lo_minus {
			gpios = < &gpio0 0x1b 0x10 >; /* in zephyr/trabalho/app.overlay:9 */
			label = "Lead Off Negative";  /* in zephyr/trabalho/app.overlay:10 */
		};
	};
};
